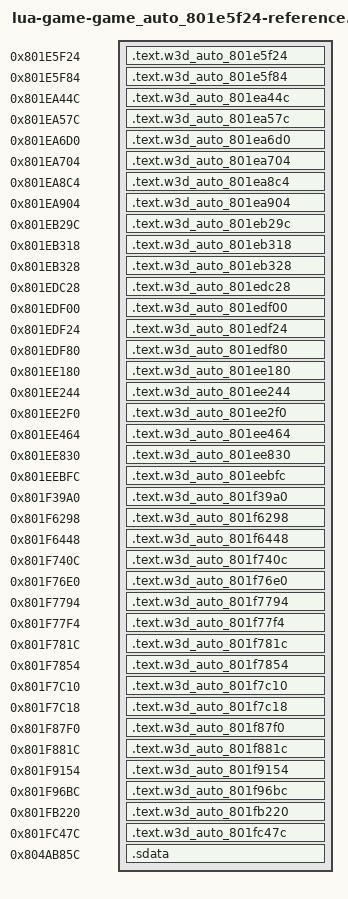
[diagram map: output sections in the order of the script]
/* Generated reference-only placements. All bodies are source-built. */
OUTPUT_FORMAT("elf32-powerpc")
OUTPUT_ARCH(powerpc)
ENTRY(w3d_auto_801e5f24)
_SDA_BASE_ = 0x804b2540;
_SDA2_BASE_ = 0x804c2540;
fn_801E44AC = 0x801e44ac;
fn_801E4548 = 0x801e4548;
fn_801E5FD4 = 0x801e5fd4;
fn_801E8D9C = 0x801e8d9c;
fn_801EDC5C = 0x801edc5c;
fn_801F3A00 = 0x801f3a00;
fn_801F606C = 0x801f606c;
fn_801F65F0 = 0x801f65f0;
fn_802098B4 = 0x802098b4;
fn_80209920 = 0x80209920;
fn_8020B208 = 0x8020b208;
fn_80302104 = 0x80302104;
SECTIONS {
  .text.w3d_auto_801e5f24 0x801e5f24 : { *(.text.w3d_auto_801e5f24) }
  .text.w3d_auto_801e5f84 0x801e5f84 : { *(.text.w3d_auto_801e5f84) }
  .text.w3d_auto_801ea44c 0x801ea44c : { *(.text.w3d_auto_801ea44c) }
  .text.w3d_auto_801ea57c 0x801ea57c : { *(.text.w3d_auto_801ea57c) }
  .text.w3d_auto_801ea6d0 0x801ea6d0 : { *(.text.w3d_auto_801ea6d0) }
  .text.w3d_auto_801ea704 0x801ea704 : { *(.text.w3d_auto_801ea704) }
  .text.w3d_auto_801ea8c4 0x801ea8c4 : { *(.text.w3d_auto_801ea8c4) }
  .text.w3d_auto_801ea904 0x801ea904 : { *(.text.w3d_auto_801ea904) }
  .text.w3d_auto_801eb29c 0x801eb29c : { *(.text.w3d_auto_801eb29c) }
  .text.w3d_auto_801eb318 0x801eb318 : { *(.text.w3d_auto_801eb318) }
  .text.w3d_auto_801eb328 0x801eb328 : { *(.text.w3d_auto_801eb328) }
  .text.w3d_auto_801edc28 0x801edc28 : { *(.text.w3d_auto_801edc28) }
  .text.w3d_auto_801edf00 0x801edf00 : { *(.text.w3d_auto_801edf00) }
  .text.w3d_auto_801edf24 0x801edf24 : { *(.text.w3d_auto_801edf24) }
  .text.w3d_auto_801edf80 0x801edf80 : { *(.text.w3d_auto_801edf80) }
  .text.w3d_auto_801ee180 0x801ee180 : { *(.text.w3d_auto_801ee180) }
  .text.w3d_auto_801ee244 0x801ee244 : { *(.text.w3d_auto_801ee244) }
  .text.w3d_auto_801ee2f0 0x801ee2f0 : { *(.text.w3d_auto_801ee2f0) }
  .text.w3d_auto_801ee464 0x801ee464 : { *(.text.w3d_auto_801ee464) }
  .text.w3d_auto_801ee830 0x801ee830 : { *(.text.w3d_auto_801ee830) }
  .text.w3d_auto_801eebfc 0x801eebfc : { *(.text.w3d_auto_801eebfc) }
  .text.w3d_auto_801f39a0 0x801f39a0 : { *(.text.w3d_auto_801f39a0) }
  .text.w3d_auto_801f6298 0x801f6298 : { *(.text.w3d_auto_801f6298) }
  .text.w3d_auto_801f6448 0x801f6448 : { *(.text.w3d_auto_801f6448) }
  .text.w3d_auto_801f740c 0x801f740c : { *(.text.w3d_auto_801f740c) }
  .text.w3d_auto_801f76e0 0x801f76e0 : { *(.text.w3d_auto_801f76e0) }
  .text.w3d_auto_801f7794 0x801f7794 : { *(.text.w3d_auto_801f7794) }
  .text.w3d_auto_801f77f4 0x801f77f4 : { *(.text.w3d_auto_801f77f4) }
  .text.w3d_auto_801f781c 0x801f781c : { *(.text.w3d_auto_801f781c) }
  .text.w3d_auto_801f7854 0x801f7854 : { *(.text.w3d_auto_801f7854) }
  .text.w3d_auto_801f7c10 0x801f7c10 : { *(.text.w3d_auto_801f7c10) }
  .text.w3d_auto_801f7c18 0x801f7c18 : { *(.text.w3d_auto_801f7c18) }
  .text.w3d_auto_801f87f0 0x801f87f0 : { *(.text.w3d_auto_801f87f0) }
  .text.w3d_auto_801f881c 0x801f881c : { *(.text.w3d_auto_801f881c) }
  .text.w3d_auto_801f9154 0x801f9154 : { *(.text.w3d_auto_801f9154) }
  .text.w3d_auto_801f96bc 0x801f96bc : { *(.text.w3d_auto_801f96bc) }
  .text.w3d_auto_801fb220 0x801fb220 : { *(.text.w3d_auto_801fb220) }
  .text.w3d_auto_801fc47c 0x801fc47c : { *(.text.w3d_auto_801fc47c) }
  .sdata 0x804ab85c (NOLOAD) : {
    . = 0x0; lbl_804AB85C = .;
    . = 0x9c; lbl_804AB8F8 = .;
    . = 0x4d24; lbl_804B0580 = .;
    . = 0x4d34; lbl_804B0590 = .;
    . = 0x4d38; lbl_804B0594 = .;
    . = 0x4d3c; lbl_804B0598 = .;
    . = 0x4d40; lbl_804B059C = .;
    . = 0x4d44; lbl_804B05A0 = .;
    . = 0x4d4c; lbl_804B05A8 = .;
    . = 0x4d50; lbl_804B05AC = .;
    . = 0x4d58; lbl_804B05B4 = .;
    . += 1; }
  /DISCARD/ : { *(.text*) *(.rodata*) *(.data*) *(.bss*) *(.sdata*) *(.sbss*) *(.comment) }
}
